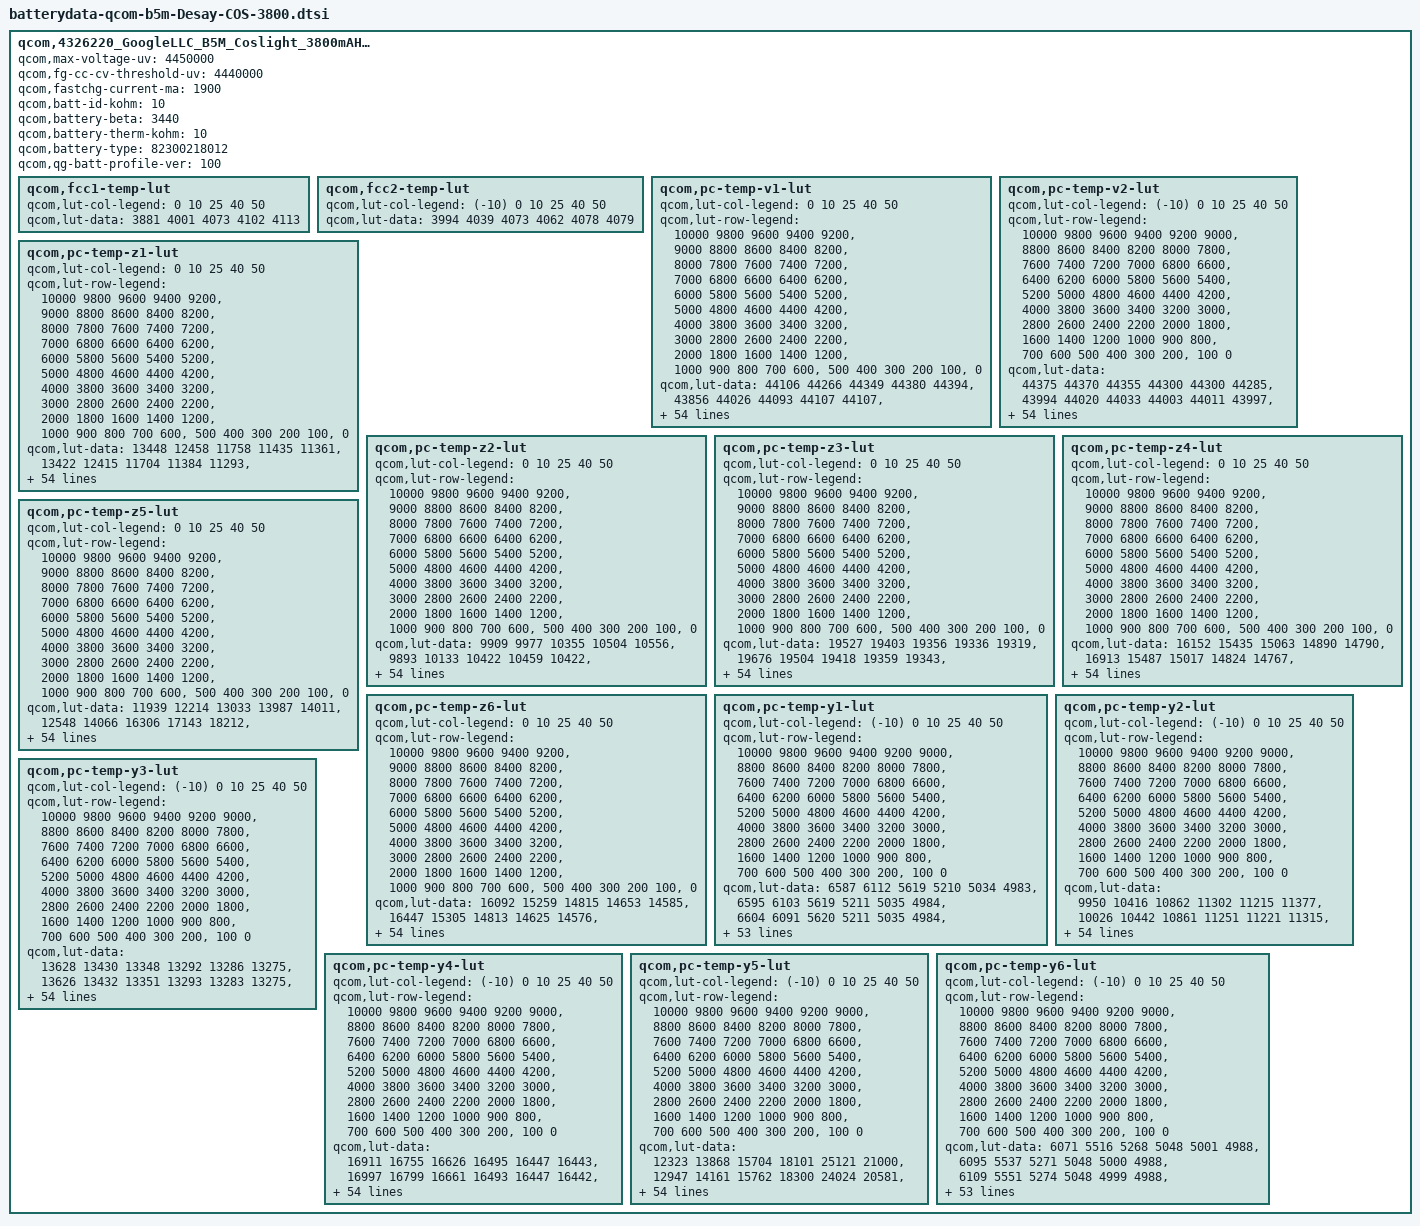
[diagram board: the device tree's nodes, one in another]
// SPDX-License-Identifier: GPL-2.0
qcom,4326220_GoogleLLC_B5M_Coslight_3800mAH_PM7250B {
	/* 4326220_GoogleLLC_B5M_Coslight_3800mAH_PM7250B_Feb7th2020 */
	qcom,max-voltage-uv = <4450000>;
	qcom,fg-cc-cv-threshold-uv = <4440000>;
	qcom,fastchg-current-ma = <1900>;
	qcom,batt-id-kohm = <10>;
	qcom,battery-beta = <3440>;
	qcom,battery-therm-kohm = <10>;
	qcom,battery-type = "82300218012";
	qcom,qg-batt-profile-ver = <100>;

	qcom,fcc1-temp-lut {
		qcom,lut-col-legend = <0 10 25 40 50>;
		qcom,lut-data = <3881 4001 4073 4102 4113>;
	};

	qcom,fcc2-temp-lut {
		qcom,lut-col-legend = <(-10) 0 10 25 40 50>;
		qcom,lut-data = <3994 4039 4073 4062 4078 4079>;
	};

	qcom,pc-temp-v1-lut {
		qcom,lut-col-legend = <0 10 25 40 50>;
		qcom,lut-row-legend = <10000 9800 9600 9400 9200>,
			<9000 8800 8600 8400 8200>,
			<8000 7800 7600 7400 7200>,
			<7000 6800 6600 6400 6200>,
			<6000 5800 5600 5400 5200>,
			<5000 4800 4600 4400 4200>,
			<4000 3800 3600 3400 3200>,
			<3000 2800 2600 2400 2200>,
			<2000 1800 1600 1400 1200>,
			<1000 900 800 700 600>,
			<500 400 300 200 100>,
			<0>;
		qcom,lut-data = <44106 44266 44349 44380 44394>,
			<43856 44026 44093 44107 44107>,
			<43611 43791 43863 43872 43869>,
			<43370 43561 43642 43649 43647>,
			<43121 43325 43412 43425 43427>,
			<42864 43082 43172 43192 43197>,
			<42609 42830 42926 42954 42960>,
			<42358 42576 42674 42706 42716>,
			<42111 42324 42421 42453 42465>,
			<41870 42074 42172 42204 42217>,
			<41636 41830 41924 41957 41971>,
			<41408 41591 41682 41714 41728>,
			<41187 41360 41442 41473 41487>,
			<40974 41140 41211 41237 41250>,
			<40760 40925 40992 41010 41023>,
			<40549 40709 40779 40789 40802>,
			<40348 40492 40565 40578 40589>,
			<40156 40287 40357 40374 40382>,
			<39975 40096 40166 40183 40187>,
			<39808 39916 39989 40004 40006>,
			<39652 39748 39814 39825 39826>,
			<39501 39589 39649 39641 39641>,
			<39354 39428 39466 39449 39451>,
			<39212 39266 39200 39229 39235>,
			<39074 39089 38925 38996 39003>,
			<38943 38858 38782 38826 38829>,
			<38819 38643 38693 38701 38701>,
			<38701 38524 38604 38591 38589>,
			<38592 38441 38507 38485 38482>,
			<38491 38373 38416 38390 38384>,
			<38402 38315 38338 38307 38296>,
			<38330 38265 38268 38232 38214>,
			<38271 38220 38205 38164 38142>,
			<38222 38178 38149 38101 38078>,
			<38187 38142 38101 38045 38018>,
			<38155 38108 38061 37998 37964>,
			<38123 38073 38021 37950 37907>,
			<38092 38040 37979 37898 37841>,
			<38052 37998 37930 37838 37765>,
			<37992 37927 37856 37760 37682>,
			<37914 37823 37748 37658 37587>,
			<37809 37708 37627 37542 37476>,
			<37672 37574 37491 37406 37338>,
			<37517 37419 37334 37254 37184>,
			<37368 37259 37172 37097 37029>,
			<37247 37148 37076 37004 36945>,
			<37196 37115 37050 36982 36922>,
			<37159 37087 37033 36965 36907>,
			<37120 37065 37012 36951 36893>,
			<37082 37033 36979 36916 36850>,
			<37014 36888 36802 36710 36629>,
			<36738 36488 36382 36273 36183>,
			<36224 35906 35803 35695 35605>,
			<35516 35090 35010 34907 34810>,
			<34325 33734 33779 33675 33567>,
			<30000 30000 30000 30000 30000>;
	};

	qcom,pc-temp-v2-lut {
		qcom,lut-col-legend = <(-10) 0 10 25 40 50>;
		qcom,lut-row-legend = <10000 9800 9600 9400 9200 9000>,
			<8800 8600 8400 8200 8000 7800>,
			<7600 7400 7200 7000 6800 6600>,
			<6400 6200 6000 5800 5600 5400>,
			<5200 5000 4800 4600 4400 4200>,
			<4000 3800 3600 3400 3200 3000>,
			<2800 2600 2400 2200 2000 1800>,
			<1600 1400 1200 1000 900 800>,
			<700 600 500 400 300 200>,
			<100 0>;
		qcom,lut-data = <44375 44370 44355 44300 44300 44285>,
			<43994 44020 44033 44003 44011 43997>,
			<43660 43710 43742 43730 43744 43729>,
			<43383 43448 43488 43484 43499 43486>,
			<43151 43224 43263 43262 43274 43262>,
			<42913 42989 43028 43030 43041 43031>,
			<42661 42738 42779 42785 42798 42789>,
			<42409 42486 42529 42538 42553 42545>,
			<42170 42234 42278 42289 42305 42298>,
			<41934 41985 42028 42041 42057 42051>,
			<41680 41750 41782 41797 41813 41807>,
			<41403 41528 41541 41557 41574 41566>,
			<41148 41303 41308 41322 41339 41331>,
			<40942 41072 41080 41089 41106 41100>,
			<40740 40841 40861 40865 40880 40877>,
			<40488 40612 40654 40649 40662 40659>,
			<40199 40381 40450 40440 40451 40448>,
			<39932 40134 40235 40238 40249 40246>,
			<39678 39869 40014 40043 40055 40052>,
			<39451 39627 39783 39850 39868 39866>,
			<39263 39415 39535 39664 39696 39695>,
			<39095 39220 39300 39466 39506 39507>,
			<38929 39037 39093 39220 39254 39259>,
			<38768 38868 38905 38967 38998 39007>,
			<38598 38713 38744 38787 38817 38825>,
			<38393 38573 38602 38647 38672 38676>,
			<38221 38428 38475 38523 38545 38547>,
			<38135 38251 38360 38410 38433 38435>,
			<38074 38096 38252 38308 38333 38334>,
			<38013 38013 38146 38213 38239 38240>,
			<37955 37955 38048 38126 38154 38154>,
			<37896 37903 37960 38049 38078 38077>,
			<37838 37856 37881 37979 38008 38007>,
			<37778 37809 37821 37912 37940 37939>,
			<37718 37760 37778 37850 37878 37877>,
			<37657 37711 37737 37790 37808 37802>,
			<37592 37656 37696 37729 37719 37694>,
			<37523 37598 37653 37668 37623 37574>,
			<37451 37536 37600 37595 37532 37477>,
			<37378 37471 37535 37512 37445 37389>,
			<37305 37391 37445 37428 37366 37309>,
			<37233 37288 37332 37332 37274 37219>,
			<37159 37162 37202 37201 37147 37090>,
			<37087 37036 37035 37072 37019 36958>,
			<37004 36902 36883 36904 36866 36814>,
			<36912 36796 36782 36852 36830 36784>,
			<36866 36753 36746 36841 36820 36773>,
			<36813 36719 36708 36823 36806 36759>,
			<36755 36685 36664 36799 36783 36735>,
			<36695 36640 36591 36745 36715 36656>,
			<36605 36551 36410 36536 36435 36346>,
			<36462 36309 35998 36076 35937 35840>,
			<36169 35747 35371 35431 35272 35170>,
			<35638 34851 34405 34547 34340 34229>,
			<34783 33573 32861 33159 32886 32762>,
			<33570 31705 28983 28570 27979 27883>;
	};

	qcom,pc-temp-z1-lut {
		qcom,lut-col-legend = <0 10 25 40 50>;
		qcom,lut-row-legend = <10000 9800 9600 9400 9200>,
			<9000 8800 8600 8400 8200>,
			<8000 7800 7600 7400 7200>,
			<7000 6800 6600 6400 6200>,
			<6000 5800 5600 5400 5200>,
			<5000 4800 4600 4400 4200>,
			<4000 3800 3600 3400 3200>,
			<3000 2800 2600 2400 2200>,
			<2000 1800 1600 1400 1200>,
			<1000 900 800 700 600>,
			<500 400 300 200 100>,
			<0>;
		qcom,lut-data = <13448 12458 11758 11435 11361>,
			<13422 12415 11704 11384 11293>,
			<13373 12398 11678 11366 11274>,
			<13347 12368 11661 11356 11268>,
			<13329 12343 11636 11342 11260>,
			<13330 12322 11624 11334 11255>,
			<13333 12308 11614 11328 11251>,
			<13324 12294 11604 11325 11250>,
			<13305 12275 11596 11322 11249>,
			<13274 12254 11591 11320 11248>,
			<13216 12243 11588 11319 11247>,
			<13164 12237 11588 11318 11246>,
			<13115 12235 11590 11317 11245>,
			<13078 12237 11591 11316 11245>,
			<13068 12240 11590 11315 11245>,
			<13055 12243 11588 11315 11246>,
			<13048 12247 11586 11315 11246>,
			<13038 12247 11583 11316 11246>,
			<13032 12245 11583 11316 11246>,
			<13039 12243 11587 11318 11247>,
			<13054 12249 11590 11319 11249>,
			<13063 12263 11595 11321 11251>,
			<13068 12271 11600 11322 11252>,
			<13070 12277 11606 11325 11254>,
			<13082 12280 11613 11328 11256>,
			<13111 12283 11618 11332 11259>,
			<13127 12286 11622 11335 11261>,
			<13143 12292 11627 11339 11264>,
			<13155 12304 11634 11342 11267>,
			<13163 12314 11640 11346 11269>,
			<13170 12327 11644 11349 11271>,
			<13175 12339 11648 11352 11273>,
			<13173 12347 11652 11355 11276>,
			<13170 12357 11658 11359 11279>,
			<13191 12372 11664 11363 11282>,
			<13219 12393 11670 11366 11285>,
			<13230 12401 11677 11371 11288>,
			<13249 12401 11682 11375 11291>,
			<13255 12401 11688 11380 11293>,
			<13250 12416 11693 11385 11296>,
			<13252 12445 11698 11388 11298>,
			<13285 12455 11704 11391 11301>,
			<13337 12458 11713 11393 11303>,
			<13351 12466 11719 11394 11305>,
			<13355 12481 11723 11396 11306>,
			<13350 12506 11729 11403 11308>,
			<13343 12513 11731 11402 11308>,
			<13379 12500 11738 11402 11309>,
			<13314 12482 11736 11404 11311>,
			<13333 12484 11738 11407 11314>,
			<13349 12515 11750 11414 11318>,
			<13369 12550 11760 11422 11323>,
			<13417 12566 11778 11432 11332>,
			<13433 12627 11813 11451 11346>,
			<13433 12627 11813 11451 11346>,
			<13433 12627 11813 11451 11346>;
	};

	qcom,pc-temp-z2-lut {
		qcom,lut-col-legend = <0 10 25 40 50>;
		qcom,lut-row-legend = <10000 9800 9600 9400 9200>,
			<9000 8800 8600 8400 8200>,
			<8000 7800 7600 7400 7200>,
			<7000 6800 6600 6400 6200>,
			<6000 5800 5600 5400 5200>,
			<5000 4800 4600 4400 4200>,
			<4000 3800 3600 3400 3200>,
			<3000 2800 2600 2400 2200>,
			<2000 1800 1600 1400 1200>,
			<1000 900 800 700 600>,
			<500 400 300 200 100>,
			<0>;
		qcom,lut-data = <9909 9977 10355 10504 10556>,
			<9893 10133 10422 10459 10422>,
			<10028 10211 10466 10485 10442>,
			<10086 10239 10468 10492 10456>,
			<10085 10190 10409 10550 10448>,
			<10040 10152 10355 10493 10404>,
			<10009 10140 10324 10442 10368>,
			<10009 10132 10307 10437 10362>,
			<10012 10125 10299 10434 10359>,
			<10014 10119 10308 10416 10363>,
			<10016 10110 10327 10376 10375>,
			<10017 10098 10343 10365 10387>,
			<10014 10090 10358 10380 10397>,
			<10011 10168 10370 10397 10407>,
			<10011 10285 10379 10409 10423>,
			<10012 10272 10389 10421 10440>,
			<10011 10167 10400 10433 10453>,
			<10004 10130 10414 10446 10464>,
			<9997 10148 10429 10454 10476>,
			<9996 10172 10447 10461 10491>,
			<9995 10198 10462 10465 10506>,
			<9993 10227 10476 10485 10516>,
			<9988 10254 10486 10509 10526>,
			<9985 10283 10484 10505 10543>,
			<9988 10306 10476 10491 10568>,
			<9995 10324 10469 10494 10565>,
			<10003 10337 10452 10533 10482>,
			<10015 10338 10449 10552 10405>,
			<10028 10335 10478 10506 10359>,
			<10040 10335 10500 10447 10330>,
			<10052 10336 10492 10421 10340>,
			<10063 10339 10478 10403 10374>,
			<10074 10347 10484 10413 10410>,
			<10082 10360 10511 10487 10452>,
			<10088 10369 10540 10560 10503>,
			<10095 10380 10574 10625 10580>,
			<10104 10392 10601 10671 10647>,
			<10116 10407 10612 10685 10675>,
			<10127 10420 10622 10694 10693>,
			<10139 10430 10646 10715 10713>,
			<10148 10440 10690 10759 10736>,
			<10153 10440 10703 10775 10745>,
			<10157 10435 10689 10766 10737>,
			<10175 10433 10687 10750 10725>,
			<10114 10446 10701 10719 10716>,
			<9889 10571 10742 10777 10761>,
			<9869 10558 10717 10777 10764>,
			<9740 10504 10687 10758 10766>,
			<9734 10594 10679 10785 10818>,
			<9678 10684 10714 10879 10890>,
			<9584 10581 10762 10790 10743>,
			<9554 10432 10757 10651 10555>,
			<9660 10291 10695 10552 10503>,
			<9584 10200 10548 10540 10431>,
			<9584 10200 10548 10540 10431>,
			<9584 10200 10548 10540 10431>;
	};

	qcom,pc-temp-z3-lut {
		qcom,lut-col-legend = <0 10 25 40 50>;
		qcom,lut-row-legend = <10000 9800 9600 9400 9200>,
			<9000 8800 8600 8400 8200>,
			<8000 7800 7600 7400 7200>,
			<7000 6800 6600 6400 6200>,
			<6000 5800 5600 5400 5200>,
			<5000 4800 4600 4400 4200>,
			<4000 3800 3600 3400 3200>,
			<3000 2800 2600 2400 2200>,
			<2000 1800 1600 1400 1200>,
			<1000 900 800 700 600>,
			<500 400 300 200 100>,
			<0>;
		qcom,lut-data = <19527 19403 19356 19336 19319>,
			<19676 19504 19418 19359 19343>,
			<19678 19549 19426 19361 19341>,
			<19659 19618 19429 19364 19339>,
			<19648 19624 19469 19398 19367>,
			<19637 19625 19469 19395 19367>,
			<19632 19622 19468 19391 19366>,
			<19638 19617 19462 19387 19364>,
			<19648 19612 19453 19383 19360>,
			<19655 19604 19443 19376 19355>,
			<19660 19593 19432 19367 19350>,
			<19662 19576 19429 19362 19347>,
			<19659 19562 19428 19360 19345>,
			<19655 19561 19425 19358 19343>,
			<19648 19564 19413 19357 19339>,
			<19637 19554 19404 19356 19334>,
			<19628 19528 19402 19353 19332>,
			<19618 19513 19401 19347 19332>,
			<19612 19510 19399 19345 19331>,
			<19614 19507 19396 19343 19329>,
			<19622 19502 19396 19342 19328>,
			<19631 19496 19398 19348 19330>,
			<19646 19496 19402 19355 19333>,
			<19659 19501 19408 19351 19334>,
			<19664 19507 19414 19340 19334>,
			<19667 19519 19410 19342 19336>,
			<19668 19529 19394 19368 19350>,
			<19668 19529 19390 19382 19358>,
			<19668 19524 19408 19382 19357>,
			<19667 19519 19423 19381 19355>,
			<19666 19514 19424 19375 19352>,
			<19664 19510 19423 19365 19348>,
			<19658 19507 19421 19361 19344>,
			<19651 19505 19418 19360 19340>,
			<19644 19503 19414 19358 19336>,
			<19636 19502 19410 19355 19332>,
			<19628 19501 19407 19352 19329>,
			<19620 19498 19405 19351 19330>,
			<19613 19495 19403 19350 19332>,
			<19605 19491 19401 19349 19332>,
			<19598 19487 19399 19347 19329>,
			<19590 19482 19396 19345 19328>,
			<19582 19479 19392 19343 19329>,
			<19572 19472 19390 19342 19331>,
			<19512 19459 19388 19341 19333>,
			<19370 19426 19371 19336 19322>,
			<19363 19416 19367 19330 19321>,
			<19314 19388 19358 19330 19317>,
			<19307 19328 19355 19324 19309>,
			<19303 19304 19353 19318 19308>,
			<19284 19324 19349 19331 19320>,
			<19287 19346 19346 19340 19330>,
			<19356 19355 19345 19344 19328>,
			<19418 19409 19353 19335 19329>,
			<19418 19409 19353 19335 19329>,
			<19418 19409 19353 19335 19329>;
	};

	qcom,pc-temp-z4-lut {
		qcom,lut-col-legend = <0 10 25 40 50>;
		qcom,lut-row-legend = <10000 9800 9600 9400 9200>,
			<9000 8800 8600 8400 8200>,
			<8000 7800 7600 7400 7200>,
			<7000 6800 6600 6400 6200>,
			<6000 5800 5600 5400 5200>,
			<5000 4800 4600 4400 4200>,
			<4000 3800 3600 3400 3200>,
			<3000 2800 2600 2400 2200>,
			<2000 1800 1600 1400 1200>,
			<1000 900 800 700 600>,
			<500 400 300 200 100>,
			<0>;
		qcom,lut-data = <16152 15435 15063 14890 14790>,
			<16913 15487 15017 14824 14767>,
			<16940 15249 14892 14759 14732>,
			<16614 15564 14844 14727 14704>,
			<16335 15369 14955 14809 14772>,
			<16080 15185 14880 14781 14754>,
			<15856 15080 14820 14749 14730>,
			<15671 14997 14778 14730 14717>,
			<15513 14932 14750 14715 14708>,
			<15388 14879 14740 14709 14701>,
			<15284 14842 14734 14705 14696>,
			<15199 14815 14724 14701 14691>,
			<15128 14792 14712 14694 14684>,
			<15070 14761 14706 14686 14678>,
			<15026 14732 14705 14679 14674>,
			<14991 14732 14703 14672 14670>,
			<14971 14751 14700 14670 14665>,
			<14962 14757 14696 14668 14659>,
			<14953 14747 14691 14666 14655>,
			<14934 14737 14686 14661 14651>,
			<14903 14732 14685 14659 14649>,
			<14873 14728 14686 14664 14656>,
			<14844 14728 14688 14676 14671>,
			<14822 14729 14750 14717 14703>,
			<14811 14733 14840 14789 14754>,
			<14803 14785 14847 14798 14764>,
			<14802 14846 14830 14751 14732>,
			<14805 14848 14808 14714 14703>,
			<14809 14839 14771 14698 14690>,
			<14816 14828 14740 14687 14681>,
			<14823 14815 14724 14683 14673>,
			<14825 14801 14714 14680 14668>,
			<14825 14787 14712 14677 14664>,
			<14825 14775 14711 14673 14660>,
			<14821 14766 14711 14671 14659>,
			<14812 14758 14711 14674 14662>,
			<14804 14752 14712 14678 14666>,
			<14795 14744 14713 14681 14672>,
			<14785 14740 14714 14684 14680>,
			<14775 14741 14716 14688 14681>,
			<14765 14743 14719 14691 14680>,
			<14759 14741 14719 14691 14677>,
			<14753 14730 14712 14685 14672>,
			<14737 14720 14706 14684 14670>,
			<14753 14705 14699 14685 14674>,
			<14844 14675 14664 14657 14654>,
			<14848 14675 14658 14652 14645>,
			<14895 14697 14652 14638 14635>,
			<14897 14756 14643 14631 14626>,
			<14895 14775 14640 14633 14624>,
			<14907 14755 14656 14635 14629>,
			<14914 14748 14665 14633 14629>,
			<14868 14751 14666 14630 14631>,
			<14845 14725 14661 14637 14629>,
			<14845 14725 14661 14637 14629>,
			<14845 14725 14661 14637 14629>;
	};

	qcom,pc-temp-z5-lut {
		qcom,lut-col-legend = <0 10 25 40 50>;
		qcom,lut-row-legend = <10000 9800 9600 9400 9200>,
			<9000 8800 8600 8400 8200>,
			<8000 7800 7600 7400 7200>,
			<7000 6800 6600 6400 6200>,
			<6000 5800 5600 5400 5200>,
			<5000 4800 4600 4400 4200>,
			<4000 3800 3600 3400 3200>,
			<3000 2800 2600 2400 2200>,
			<2000 1800 1600 1400 1200>,
			<1000 900 800 700 600>,
			<500 400 300 200 100>,
			<0>;
		qcom,lut-data = <11939 12214 13033 13987 14011>,
			<12548 14066 16306 17143 18212>,
			<12617 16212 18683 19476 19337>,
			<12918 14493 19671 21890 20997>,
			<13265 14835 17347 19639 19780>,
			<13747 15284 18058 19595 20004>,
			<14283 15818 18782 19679 20372>,
			<14827 16439 19854 20307 20811>,
			<15379 17112 20552 21167 21252>,
			<15900 17889 20315 20913 21190>,
			<16404 18475 19940 19794 20641>,
			<16818 18898 20255 19462 20431>,
			<17197 19257 21513 19926 20949>,
			<17448 21115 21892 20552 21410>,
			<17442 23622 20743 21395 21128>,
			<17309 23270 19843 22139 20633>,
			<17101 20786 20134 21907 20820>,
			<16558 19864 20797 21134 21931>,
			<16105 20734 21479 20998 22968>,
			<16251 21881 22337 21652 23820>,
			<16879 22651 23597 22744 24636>,
			<17795 23417 25986 26535 25754>,
			<19577 24795 28252 30384 26737>,
			<21715 27858 30077 27130 24560>,
			<23839 31710 31560 18908 18167>,
			<26050 38474 29376 17146 16444>,
			<28060 44356 21565 18828 17776>,
			<30033 42837 18913 20850 19411>,
			<31747 37115 20927 23389 20941>,
			<33365 33280 23434 25214 22507>,
			<34588 30773 25639 25214 23935>,
			<34646 29609 28108 25088 25288>,
			<34107 29698 30497 25850 26680>,
			<33472 29930 32908 29809 28254>,
			<32464 30451 34049 31917 28869>,
			<31358 31696 34542 32034 28613>,
			<30680 32752 34742 31901 28354>,
			<30150 33608 34308 31277 28433>,
			<29997 34125 33378 30084 28597>,
			<30105 34111 32402 28667 28019>,
			<30219 33932 31230 26758 25370>,
			<30208 33604 30119 25562 24273>,
			<30104 32737 28971 25001 25116>,
			<29793 31670 28834 24437 25308>,
			<24818 31098 29424 23023 24318>,
			<13073 29803 29923 26067 22738>,
			<12796 24439 28660 23846 23438>,
			<11753 19133 25205 26723 24335>,
			<11597 13187 25274 26673 24341>,
			<11524 12319 25685 22759 24490>,
			<11277 13359 21497 24644 25141>,
			<11334 14024 18447 26564 27089>,
			<12304 14085 17599 27615 23562>,
			<13619 21346 18644 21319 23576>,
			<13619 21346 18644 21319 23576>,
			<13619 21346 18644 21319 23576>;
	};

	qcom,pc-temp-z6-lut {
		qcom,lut-col-legend = <0 10 25 40 50>;
		qcom,lut-row-legend = <10000 9800 9600 9400 9200>,
			<9000 8800 8600 8400 8200>,
			<8000 7800 7600 7400 7200>,
			<7000 6800 6600 6400 6200>,
			<6000 5800 5600 5400 5200>,
			<5000 4800 4600 4400 4200>,
			<4000 3800 3600 3400 3200>,
			<3000 2800 2600 2400 2200>,
			<2000 1800 1600 1400 1200>,
			<1000 900 800 700 600>,
			<500 400 300 200 100>,
			<0>;
		qcom,lut-data = <16092 15259 14815 14653 14585>,
			<16447 15305 14813 14625 14576>,
			<16436 15202 14757 14595 14556>,
			<16243 15357 14732 14580 14542>,
			<16082 15261 14797 14632 14586>,
			<15942 15167 14761 14618 14578>,
			<15822 15108 14729 14601 14567>,
			<15727 15059 14705 14590 14559>,
			<15646 15019 14687 14581 14553>,
			<15579 14984 14675 14573 14547>,
			<15521 14956 14667 14567 14542>,
			<15469 14932 14660 14562 14538>,
			<15419 14913 14654 14557 14534>,
			<15376 14901 14649 14553 14530>,
			<15341 14891 14642 14549 14526>,
			<15311 14883 14636 14546 14521>,
			<15294 14877 14633 14542 14518>,
			<15287 14871 14630 14539 14516>,
			<15281 14865 14628 14536 14513>,
			<15276 14861 14625 14534 14511>,
			<15272 14858 14624 14533 14509>,
			<15271 14856 14626 14537 14513>,
			<15272 14856 14631 14547 14522>,
			<15274 14861 14662 14565 14537>,
			<15278 14869 14705 14590 14560>,
			<15282 14901 14706 14595 14566>,
			<15288 14933 14692 14589 14560>,
			<15295 14934 14683 14583 14553>,
			<15302 14931 14678 14577 14547>,
			<15310 14927 14674 14571 14542>,
			<15316 14921 14669 14565 14537>,
			<15318 14916 14665 14560 14533>,
			<15319 14911 14663 14557 14529>,
			<15320 14906 14662 14555 14525>,
			<15319 14905 14662 14554 14523>,
			<15318 14903 14661 14553 14522>,
			<15316 14903 14661 14553 14522>,
			<15312 14904 14662 14554 14524>,
			<15311 14905 14663 14556 14530>,
			<15314 14908 14664 14557 14530>,
			<15317 14911 14666 14558 14529>,
			<15318 14912 14666 14558 14527>,
			<15319 14910 14663 14555 14526>,
			<15318 14908 14661 14554 14526>,
			<15308 14903 14660 14555 14529>,
			<15287 14879 14638 14541 14515>,
			<15287 14875 14634 14535 14511>,
			<15282 14871 14627 14530 14504>,
			<15282 14867 14623 14523 14496>,
			<15285 14868 14623 14522 14495>,
			<15292 14877 14631 14531 14505>,
			<15309 14894 14638 14537 14512>,
			<15341 14915 14643 14540 14514>,
			<15388 14953 14655 14542 14517>,
			<15388 14953 14655 14542 14517>,
			<15388 14953 14655 14542 14517>;
	};

	qcom,pc-temp-y1-lut {
		qcom,lut-col-legend = <(-10) 0 10 25 40 50>;
		qcom,lut-row-legend = <10000 9800 9600 9400 9200 9000>,
			<8800 8600 8400 8200 8000 7800>,
			<7600 7400 7200 7000 6800 6600>,
			<6400 6200 6000 5800 5600 5400>,
			<5200 5000 4800 4600 4400 4200>,
			<4000 3800 3600 3400 3200 3000>,
			<2800 2600 2400 2200 2000 1800>,
			<1600 1400 1200 1000 900 800>,
			<700 600 500 400 300 200>,
			<100 0>;
		qcom,lut-data = <6587 6112 5619 5210 5034 4983>,
			<6595 6103 5619 5211 5035 4984>,
			<6604 6091 5620 5211 5035 4984>,
			<6613 6079 5620 5210 5035 4984>,
			<6619 6069 5620 5208 5035 4984>,
			<6621 6062 5620 5206 5034 4984>,
			<6617 6056 5619 5202 5033 4983>,
			<6612 6052 5617 5199 5031 4983>,
			<6611 6058 5611 5197 5030 4982>,
			<6612 6067 5604 5195 5029 4982>,
			<6616 6069 5603 5194 5028 4981>,
			<6622 6070 5605 5193 5027 4980>,
			<6626 6070 5606 5192 5026 4980>,
			<6627 6076 5608 5192 5025 4980>,
			<6628 6081 5611 5192 5024 4979>,
			<6640 6085 5614 5191 5024 4980>,
			<6666 6092 5616 5190 5024 4980>,
			<6676 6090 5619 5191 5024 4980>,
			<6678 6076 5623 5193 5024 4980>,
			<6678 6071 5622 5194 5024 4980>,
			<6664 6081 5617 5196 5025 4981>,
			<6641 6092 5613 5197 5025 4981>,
			<6640 6091 5614 5199 5026 4982>,
			<6644 6087 5617 5200 5027 4982>,
			<6648 6087 5621 5203 5028 4983>,
			<6653 6091 5627 5207 5030 4984>,
			<6656 6093 5629 5211 5031 4985>,
			<6655 6097 5633 5212 5032 4986>,
			<6654 6101 5636 5214 5034 4987>,
			<6652 6098 5635 5218 5036 4988>,
			<6643 6092 5633 5221 5038 4990>,
			<6637 6090 5634 5223 5040 4991>,
			<6633 6091 5636 5225 5043 4992>,
			<6629 6092 5638 5227 5045 4994>,
			<6629 6092 5641 5230 5047 4996>,
			<6627 6093 5642 5232 5049 4998>,
			<6626 6095 5641 5236 5051 4998>,
			<6619 6099 5639 5239 5052 4999>,
			<6614 6099 5640 5242 5054 5000>,
			<6642 6091 5642 5244 5055 5002>,
			<6673 6081 5651 5250 5057 5002>,
			<6656 6072 5659 5255 5059 5004>,
			<6646 6109 5683 5256 5061 5006>,
			<6715 6142 5673 5259 5064 5009>,
			<6730 6165 5682 5261 5067 5011>,
			<6740 6150 5700 5270 5071 5013>,
			<6723 6159 5686 5271 5070 5013>,
			<6742 6161 5679 5272 5072 5013>,
			<6726 6151 5683 5281 5073 5015>,
			<6749 6156 5701 5284 5075 5014>,
			<6741 6176 5694 5285 5075 5015>,
			<6899 6200 5722 5296 5083 5021>,
			<7031 6279 5752 5312 5092 5027>,
			<7156 6388 5811 5349 5104 5037>,
			<7156 6388 5811 5349 5104 5037>,
			<7156 6388 5811 5349 5104 5037>;
	};

	qcom,pc-temp-y2-lut {
		qcom,lut-col-legend = <(-10) 0 10 25 40 50>;
		qcom,lut-row-legend = <10000 9800 9600 9400 9200 9000>,
			<8800 8600 8400 8200 8000 7800>,
			<7600 7400 7200 7000 6800 6600>,
			<6400 6200 6000 5800 5600 5400>,
			<5200 5000 4800 4600 4400 4200>,
			<4000 3800 3600 3400 3200 3000>,
			<2800 2600 2400 2200 2000 1800>,
			<1600 1400 1200 1000 900 800>,
			<700 600 500 400 300 200>,
			<100 0>;
		qcom,lut-data = <9950 10416 10862 11302 11215 11377>,
			<10026 10442 10861 11251 11221 11315>,
			<10108 10493 10854 11201 11211 11255>,
			<10186 10550 10844 11154 11189 11200>,
			<10248 10592 10832 11112 11158 11153>,
			<10286 10602 10816 11076 11122 11118>,
			<10304 10600 10787 11046 11065 11089>,
			<10324 10599 10766 11018 11027 11070>,
			<10367 10610 10756 10980 11029 11048>,
			<10433 10634 10749 10948 11038 11023>,
			<10507 10656 10754 10944 11026 11003>,
			<10604 10679 10775 10945 10990 10976>,
			<10647 10717 10797 10947 10983 10964>,
			<10644 10821 10819 10954 11017 10959>,
			<10639 10910 10850 10964 11040 10958>,
			<10549 10930 10923 10985 11027 10973>,
			<10323 10942 11015 11017 11013 10997>,
			<10216 10955 11081 11059 11032 11011>,
			<9919 10969 11135 11117 11091 11022>,
			<9699 10977 11147 11188 11172 11065>,
			<9691 10978 11137 11300 11317 11257>,
			<9687 10980 11130 11368 11398 11376>,
			<9683 10995 11131 11335 11317 11327>,
			<9680 11018 11133 11286 11212 11264>,
			<9677 11004 11140 11291 11226 11278>,
			<9675 10896 11160 11337 11295 11333>,
			<9672 10817 11182 11376 11347 11371>,
			<9670 10792 11213 11405 11397 11409>,
			<9669 10769 11229 11430 11439 11434>,
			<9667 10633 11174 11452 11473 11442>,
			<9666 10358 11098 11470 11511 11452>,
			<9665 10190 11087 11483 11553 11489>,
			<9664 9902 11084 11496 11599 11563>,
			<9663 9727 11075 11497 11632 11616>,
			<9663 9703 11024 11456 11659 11656>,
			<9662 9689 10970 11421 11670 11673>,
			<9662 9681 10931 11422 11595 11630>,
			<9662 9675 10890 11424 11503 11575>,
			<9661 9671 10841 11409 11507 11581>,
			<9661 9668 10779 11360 11538 11601>,
			<9661 9666 10694 11337 11571 11567>,
			<9661 9664 10586 11308 11531 11494>,
			<9661 9663 10589 11321 11523 11509>,
			<9660 9663 10082 11287 11534 11519>,
			<9660 9661 9838 11165 11471 11529>,
			<9660 9659 9717 11119 11374 11303>,
			<9659 9658 9689 11123 11325 11228>,
			<9658 9658 9677 11121 11303 11198>,
			<9658 9657 9668 11100 11328 11183>,
			<9657 9657 9663 11062 11299 11197>,
			<9655 9655 9659 11009 11244 11184>,
			<9651 9653 9656 10893 11164 11090>,
			<9649 9649 9654 10756 11032 10978>,
			<9648 9648 9650 10568 10982 10853>,
			<9648 9648 9650 10568 10982 10853>,
			<9648 9648 9650 10568 10982 10853>;
	};

	qcom,pc-temp-y3-lut {
		qcom,lut-col-legend = <(-10) 0 10 25 40 50>;
		qcom,lut-row-legend = <10000 9800 9600 9400 9200 9000>,
			<8800 8600 8400 8200 8000 7800>,
			<7600 7400 7200 7000 6800 6600>,
			<6400 6200 6000 5800 5600 5400>,
			<5200 5000 4800 4600 4400 4200>,
			<4000 3800 3600 3400 3200 3000>,
			<2800 2600 2400 2200 2000 1800>,
			<1600 1400 1200 1000 900 800>,
			<700 600 500 400 300 200>,
			<100 0>;
		qcom,lut-data = <13628 13430 13348 13292 13286 13275>,
			<13626 13432 13351 13293 13283 13275>,
			<13622 13436 13354 13295 13281 13275>,
			<13618 13440 13357 13296 13279 13275>,
			<13613 13443 13359 13297 13279 13275>,
			<13608 13444 13360 13298 13279 13275>,
			<13601 13444 13362 13300 13280 13276>,
			<13595 13444 13362 13300 13281 13277>,
			<13590 13440 13363 13301 13281 13277>,
			<13585 13435 13364 13301 13282 13278>,
			<13572 13436 13364 13301 13284 13279>,
			<13541 13442 13362 13302 13286 13279>,
			<13515 13444 13360 13303 13288 13280>,
			<13497 13434 13359 13303 13288 13283>,
			<13485 13420 13357 13302 13289 13284>,
			<13482 13412 13356 13303 13288 13285>,
			<13484 13405 13355 13304 13288 13285>,
			<13484 13397 13354 13304 13288 13284>,
			<13480 13390 13352 13303 13289 13283>,
			<13478 13382 13348 13303 13289 13283>,
			<13480 13373 13341 13305 13290 13285>,
			<13485 13365 13333 13306 13290 13286>,
			<13492 13359 13327 13301 13286 13283>,
			<13505 13354 13322 13294 13281 13278>,
			<13509 13349 13320 13292 13280 13276>,
			<13490 13344 13319 13292 13279 13274>,
			<13471 13340 13317 13291 13279 13274>,
			<13485 13335 13315 13290 13279 13274>,
			<13524 13330 13314 13290 13278 13274>,
			<13562 13330 13312 13289 13278 13274>,
			<13601 13334 13311 13289 13278 13274>,
			<13642 13341 13311 13289 13278 13275>,
			<13686 13355 13312 13288 13278 13275>,
			<13731 13371 13312 13288 13278 13275>,
			<13776 13386 13315 13288 13278 13275>,
			<13821 13403 13317 13288 13279 13275>,
			<13864 13428 13321 13289 13278 13274>,
			<13907 13461 13325 13290 13277 13273>,
			<13944 13500 13329 13290 13276 13273>,
			<13973 13549 13333 13289 13276 13273>,
			<13999 13602 13336 13290 13277 13274>,
			<14029 13650 13337 13290 13277 13274>,
			<14049 13658 13330 13287 13275 13272>,
			<14021 13665 13328 13289 13277 13272>,
			<14090 13787 13346 13286 13275 13272>,
			<14177 13959 13386 13290 13277 13275>,
			<14242 14054 13417 13294 13279 13276>,
			<14320 14149 13464 13296 13282 13279>,
			<14441 14236 13556 13300 13286 13282>,
			<14632 14350 13707 13304 13286 13282>,
			<15020 14568 13967 13304 13283 13278>,
			<16712 15312 14326 13307 13283 13279>,
			<22675 20509 15156 13313 13286 13282>,
			<52368 65535 21565 13328 13290 13285>,
			<52368 65535 21565 13328 13290 13285>,
			<52368 65535 21565 13328 13290 13285>;
	};

	qcom,pc-temp-y4-lut {
		qcom,lut-col-legend = <(-10) 0 10 25 40 50>;
		qcom,lut-row-legend = <10000 9800 9600 9400 9200 9000>,
			<8800 8600 8400 8200 8000 7800>,
			<7600 7400 7200 7000 6800 6600>,
			<6400 6200 6000 5800 5600 5400>,
			<5200 5000 4800 4600 4400 4200>,
			<4000 3800 3600 3400 3200 3000>,
			<2800 2600 2400 2200 2000 1800>,
			<1600 1400 1200 1000 900 800>,
			<700 600 500 400 300 200>,
			<100 0>;
		qcom,lut-data = <16911 16755 16626 16495 16447 16443>,
			<16997 16799 16661 16493 16447 16442>,
			<17112 16863 16694 16491 16447 16441>,
			<17226 16930 16721 16488 16447 16440>,
			<17308 16978 16737 16486 16448 16439>,
			<17329 16990 16739 16484 16448 16439>,
			<17315 16982 16730 16482 16448 16438>,
			<17296 16975 16719 16480 16448 16438>,
			<17278 16975 16712 16482 16449 16439>,
			<17261 16975 16707 16485 16450 16440>,
			<17252 16974 16708 16488 16451 16442>,
			<17246 16969 16714 16492 16451 16445>,
			<17244 16968 16723 16498 16451 16446>,
			<17251 16983 16735 16507 16456 16447>,
			<17259 16996 16750 16518 16462 16447>,
			<17225 16990 16773 16532 16470 16452>,
			<17123 16971 16794 16548 16480 16459>,
			<17055 16937 16790 16571 16493 16468>,
			<17018 16867 16769 16601 16507 16481>,
			<16983 16818 16740 16612 16526 16496>,
			<16946 16796 16693 16613 16556 16520>,
			<16907 16778 16650 16612 16572 16532>,
			<16858 16757 16622 16568 16532 16504>,
			<16798 16735 16600 16498 16475 16464>,
			<16748 16713 16588 16480 16457 16451>,
			<16702 16692 16579 16473 16449 16443>,
			<16674 16663 16574 16471 16447 16442>,
			<16673 16596 16570 16474 16449 16444>,
			<16673 16540 16566 16478 16452 16447>,
			<16675 16543 16552 16482 16457 16451>,
			<16682 16562 16534 16487 16464 16457>,
			<16690 16581 16517 16494 16473 16464>,
			<16694 16606 16501 16502 16484 16473>,
			<16698 16628 16499 16505 16491 16482>,
			<16701 16646 16516 16505 16497 16492>,
			<16704 16662 16540 16505 16499 16496>,
			<16706 16676 16565 16502 16486 16478>,
			<16709 16689 16591 16497 16466 16454>,
			<16712 16693 16611 16490 16456 16448>,
			<16716 16694 16626 16482 16450 16446>,
			<16720 16693 16623 16484 16454 16450>,
			<16726 16683 16614 16486 16456 16452>,
			<16726 16659 16561 16466 16445 16441>,
			<16688 16627 16567 16470 16447 16444>,
			<16689 16621 16576 16461 16433 16428>,
			<16698 16628 16600 16471 16442 16436>,
			<16707 16640 16619 16480 16451 16446>,
			<16718 16655 16644 16493 16461 16459>,
			<16736 16679 16678 16514 16479 16482>,
			<16756 16712 16730 16540 16498 16495>,
			<16779 16748 16765 16528 16460 16448>,
			<17021 16764 16759 16518 16452 16444>,
			<17960 17571 16793 16533 16461 16449>,
			<25055 29009 19065 16576 16486 16473>,
			<25055 29009 19065 16576 16486 16473>,
			<25055 29009 19065 16576 16486 16473>;
	};

	qcom,pc-temp-y5-lut {
		qcom,lut-col-legend = <(-10) 0 10 25 40 50>;
		qcom,lut-row-legend = <10000 9800 9600 9400 9200 9000>,
			<8800 8600 8400 8200 8000 7800>,
			<7600 7400 7200 7000 6800 6600>,
			<6400 6200 6000 5800 5600 5400>,
			<5200 5000 4800 4600 4400 4200>,
			<4000 3800 3600 3400 3200 3000>,
			<2800 2600 2400 2200 2000 1800>,
			<1600 1400 1200 1000 900 800>,
			<700 600 500 400 300 200>,
			<100 0>;
		qcom,lut-data = <12323 13868 15704 18101 25121 21000>,
			<12947 14161 15762 18300 24024 20581>,
			<13540 14446 15887 18410 21828 19974>,
			<14093 14706 16040 18456 19388 19359>,
			<14600 14928 16183 18465 17560 18919>,
			<15049 15101 16287 18462 17088 18814>,
			<15426 15260 16415 18422 17068 18871>,
			<15808 15341 16496 18319 17045 18906>,
			<16373 15303 16439 17771 16869 18796>,
			<16943 15241 16301 16953 16663 18571>,
			<16901 15515 16078 16542 17178 18170>,
			<16132 16567 15701 16273 18726 17555>,
			<15722 16989 15553 15892 19139 17541>,
			<16493 16816 15532 15222 18391 18944>,
			<17556 16665 15553 14686 17425 19885>,
			<18098 17355 16138 14436 16394 19179>,
			<18528 18651 17339 14283 15456 17869>,
			<18416 19038 19022 14369 15035 16583>,
			<17191 19176 21275 14875 14771 15238>,
			<16322 19229 21867 15958 14818 14951>,
			<17062 19242 21430 20141 15837 15474>,
			<18668 19316 20912 23165 17186 16334>,
			<20573 19677 20426 22320 18778 18568>,
			<23095 20429 20047 21019 20273 20806>,
			<23741 21432 20186 21047 20966 20753>,
			<18249 22972 20835 21702 21410 20057>,
			<13075 23603 21488 21908 21422 19416>,
			<13048 21185 22102 21428 20755 18742>,
			<13330 18245 22890 20976 20016 18285>,
			<13497 16970 24547 20807 19325 18066>,
			<13590 15454 26116 20681 18798 17943>,
			<13688 14748 25601 20831 18786 17960>,
			<13812 14451 23482 21503 18899 18042>,
			<13950 14402 21801 22341 19233 18222>,
			<14121 14497 20474 23578 20622 18975>,
			<14311 14622 19750 24599 21764 19846>,
			<14360 14768 19519 25073 22201 20800>,
			<14317 14964 19396 25371 22498 21728>,
			<14245 15349 19509 24893 22782 22385>,
			<14050 16232 19818 23003 23014 22833>,
			<13885 16524 19575 21687 22312 22299>,
			<13786 16315 19249 20981 20938 21711>,
			<13614 14943 20266 21286 20951 20051>,
			<13679 14845 16295 22355 22297 19236>,
			<13920 14506 15163 20143 22774 23302>,
			<13970 14336 14744 19892 19624 20110>,
			<14170 14018 14555 21098 19225 18614>,
			<14087 14201 14344 19597 18750 18749>,
			<14141 14290 14334 18579 19033 18008>,
			<14650 14428 14294 17862 18085 17166>,
			<14703 14517 14555 18126 19469 19088>,
			<13079 14227 13945 19985 21884 20199>,
			<10516 10459 13429 19225 22422 23965>,
			<9120 9024 10061 19241 24563 25890>,
			<9120 9024 10061 19241 24563 25890>,
			<9120 9024 10061 19241 24563 25890>;
	};

	qcom,pc-temp-y6-lut {
		qcom,lut-col-legend = <(-10) 0 10 25 40 50>;
		qcom,lut-row-legend = <10000 9800 9600 9400 9200 9000>,
			<8800 8600 8400 8200 8000 7800>,
			<7600 7400 7200 7000 6800 6600>,
			<6400 6200 6000 5800 5600 5400>,
			<5200 5000 4800 4600 4400 4200>,
			<4000 3800 3600 3400 3200 3000>,
			<2800 2600 2400 2200 2000 1800>,
			<1600 1400 1200 1000 900 800>,
			<700 600 500 400 300 200>,
			<100 0>;
		qcom,lut-data = <6071 5516 5268 5048 5001 4988>,
			<6095 5537 5271 5048 5000 4988>,
			<6109 5551 5274 5048 4999 4988>,
			<6116 5560 5275 5047 4998 4988>,
			<6118 5564 5275 5047 4998 4988>,
			<6117 5565 5274 5047 4998 4988>,
			<6100 5559 5268 5046 4999 4988>,
			<6080 5551 5262 5046 4999 4989>,
			<6071 5543 5257 5046 5000 4989>,
			<6063 5536 5253 5047 5001 4990>,
			<6050 5534 5251 5048 5002 4991>,
			<6027 5533 5248 5049 5004 4992>,
			<6011 5532 5248 5051 5005 4993>,
			<6007 5528 5248 5053 5007 4995>,
			<6003 5522 5249 5056 5009 4997>,
			<5987 5515 5253 5060 5011 4999>,
			<5956 5507 5258 5066 5014 5001>,
			<5930 5493 5256 5072 5017 5003>,
			<5907 5469 5248 5079 5022 5006>,
			<5893 5452 5237 5083 5028 5010>,
			<5889 5444 5219 5084 5036 5018>,
			<5887 5437 5202 5084 5041 5022>,
			<5884 5431 5190 5069 5026 5011>,
			<5881 5426 5182 5044 5006 4996>,
			<5878 5422 5178 5037 5000 4991>,
			<5867 5420 5176 5035 4997 4987>,
			<5858 5417 5176 5035 4996 4987>,
			<5872 5405 5176 5036 4997 4987>,
			<5910 5394 5176 5037 4998 4988>,
			<5947 5402 5173 5038 4999 4990>,
			<5984 5426 5170 5040 5001 4992>,
			<6022 5453 5170 5043 5004 4994>,
			<6061 5485 5171 5045 5007 4997>,
			<6099 5521 5173 5047 5010 4999>,
			<6136 5560 5186 5048 5012 5002>,
			<6171 5603 5205 5048 5013 5004>,
			<6205 5649 5226 5049 5009 4998>,
			<6238 5697 5251 5049 5002 4991>,
			<6269 5746 5275 5048 5000 4989>,
			<6295 5796 5299 5047 4998 4989>,
			<6320 5846 5320 5048 5000 4991>,
			<6349 5891 5334 5050 5001 4992>,
			<6371 5902 5299 5044 4996 4987>,
			<6354 5907 5321 5047 4998 4988>,
			<6413 6010 5374 5045 4994 4984>,
			<6488 6154 5463 5053 4998 4989>,
			<6543 6235 5523 5061 5002 4993>,
			<6611 6320 5603 5067 5007 4999>,
			<6715 6400 5718 5078 5016 5007>,
			<6885 6504 5880 5091 5022 5011>,
			<7213 6695 6118 5089 5008 4995>,
			<8663 7285 6419 5094 5007 4995>,
			<13300 11360 7089 5116 5013 5000>,
			<34323 39428 12390 5168 5026 5010>,
			<34323 39428 12390 5168 5026 5010>,
			<34323 39428 12390 5168 5026 5010>;
	};

};
